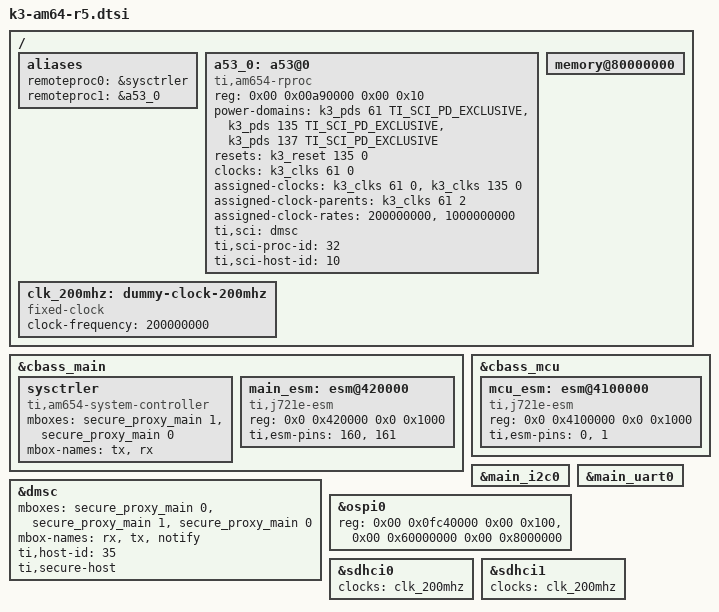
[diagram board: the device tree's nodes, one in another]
// SPDX-License-Identifier: GPL-2.0-only
/*
 * Copyright (C) 2020-2021 Texas Instruments Incorporated - https://www.ti.com/
 * Copyright (c) 2022-2023 TQ-Systems GmbH <linux@ew.tq-group.com>,
 * D-82229 Seefeld, Germany.
 *
 * Additional definitions and overrides for the R5 SPL stage of the AM64x U-Boot
 */

/ {
	aliases {
		remoteproc0 = &sysctrler;
		remoteproc1 = &a53_0;
	};

	a53_0: a53@0 {
		compatible = "ti,am654-rproc";
		reg = <0x00 0x00a90000 0x00 0x10>;
		power-domains = <&k3_pds 61 TI_SCI_PD_EXCLUSIVE>,
				<&k3_pds 135 TI_SCI_PD_EXCLUSIVE>,
				<&k3_pds 137 TI_SCI_PD_EXCLUSIVE>;
		resets = <&k3_reset 135 0>;
		clocks = <&k3_clks 61 0>;
		assigned-clocks = <&k3_clks 61 0>, <&k3_clks 135 0>;
		assigned-clock-parents = <&k3_clks 61 2>;
		assigned-clock-rates = <200000000>, <1000000000>;
		ti,sci = <&dmsc>;
		ti,sci-proc-id = <32>;
		ti,sci-host-id = <10>;
		bootph-pre-ram;
	};

	clk_200mhz: dummy-clock-200mhz {
		compatible = "fixed-clock";
		#clock-cells = <0>;
		clock-frequency = <200000000>;
		bootph-pre-ram;
	};

	memory@80000000 {
		bootph-pre-ram;
	};
};

&cbass_main {
	sysctrler: sysctrler {
		compatible = "ti,am654-system-controller";
		mboxes = <&secure_proxy_main 1>, <&secure_proxy_main 0>;
		mbox-names = "tx", "rx";
		bootph-pre-ram;
	};

	main_esm: esm@420000 {
		compatible = "ti,j721e-esm";
		reg = <0x0 0x420000 0x0 0x1000>;
		ti,esm-pins = <160>, <161>;
		bootph-pre-ram;
	};
};

&cbass_mcu {
	bootph-pre-ram;

	mcu_esm: esm@4100000 {
		compatible = "ti,j721e-esm";
		reg = <0x0 0x4100000 0x0 0x1000>;
		ti,esm-pins = <0>, <1>;
		bootph-pre-ram;
	};
};

&dmsc {
	mboxes = <&secure_proxy_main 0>,
		 <&secure_proxy_main 1>,
		 <&secure_proxy_main 0>;
	mbox-names = "rx", "tx", "notify";
	ti,host-id = <35>;
	ti,secure-host;
};

/* EEPROM might be read before SYSFW is available */
&main_i2c0 {
	/delete-property/ power-domains;
};

&main_uart0 {
	/delete-property/ power-domains;
	/delete-property/ clocks;
	/delete-property/ clock-names;
};

&ospi0 {
	reg = <0x00 0x0fc40000 0x00 0x100>,
	      <0x00 0x60000000 0x00 0x8000000>;
};

&sdhci0 {
	/* Peripheral clock set to 200MHz by boot ROM */
	clocks = <&clk_200mhz>;
	clock-names = "clk_xin";
	/delete-property/ power-domains;
};

&sdhci1 {
	clocks = <&clk_200mhz>;
	clock-names = "clk_xin";
	/delete-property/ power-domains;
};
